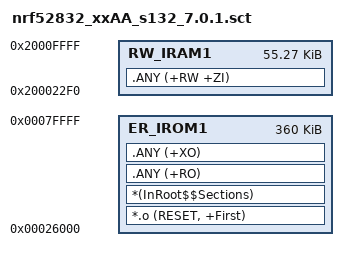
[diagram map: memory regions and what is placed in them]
; *************************************************************
; *** Scatter-Loading Description File generated by uVision ***
; *************************************************************

LR_IROM1 0x00026000 0x0005A000  {    ; load region size_region
  ER_IROM1 0x00026000 0x0005A000  {  ; load address = execution address
;LR_IROM1 0x00000000 0x0005A000  {    ; load region size_region
;  ER_IROM1 0x00000000 0x0005A000  {  ; load address = execution address
   *.o (RESET, +First)
   *(InRoot$$Sections)
   .ANY (+RO)
   .ANY (+XO)
  }
  RW_IRAM1 0x200022F0 0x0000DD10  {  ; RW data
   .ANY (+RW +ZI)
  }
}

